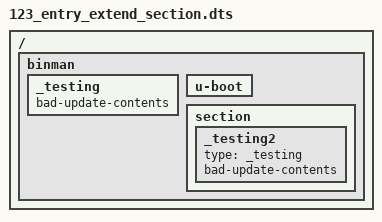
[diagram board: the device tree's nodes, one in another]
/dts-v1/;

/ {
	#address-cells = <1>;
	#size-cells = <1>;

	binman {
		_testing {
			bad-update-contents;
		};

		u-boot {
		};

		section {
			_testing2 {
				type = "_testing";
				bad-update-contents;
			};
		};
	};
};
